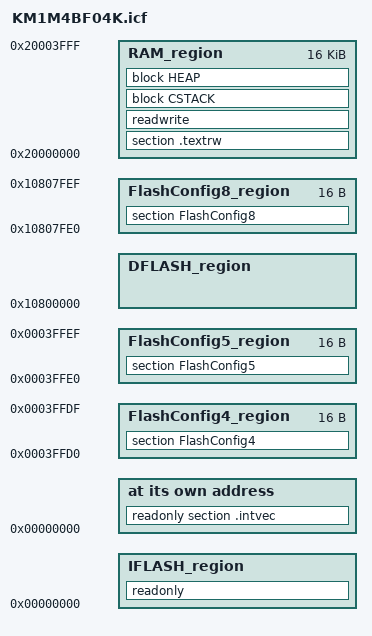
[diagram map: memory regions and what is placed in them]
/*###ICF### Section handled by ICF editor, don't touch! ****/
/*-Editor annotation file-*/
/* IcfEditorFile="$TOOLKIT_DIR$\config\ide\IcfEditor\cortex_v1_0.xml" */
/*-Specials-*/
define symbol __ICFEDIT_intvec_start__ = 0x00000000;
/*-Memory Regions-*/
define symbol __ICFEDIT_region_RAM_start__       = 0x20000000;
define symbol __ICFEDIT_region_RAM_end__         = 0x20003FFF;
define symbol __ICFEDIT_region_DFLASH_start__    = 0x10800000;
define symbol __ICFEDIT_region_DFLASH_end__      = 0x10807FFF;
define symbol __ICFEDIT_region_IFLASH_start__    = 0x00000000;
define symbol __ICFEDIT_region_IFLASH_end__      = 0x00041FFF;
/*-Sizes-*/
define symbol __ICFEDIT_size_cstack__ = 0x400;
define symbol __ICFEDIT_size_heap__   = 0x800;
/**** End of ICF editor section. ###ICF###*/

/**** Special settings for target device ****/

/*- Define symbols -*/
define symbol __FlashConfig1_start__ = 0x0003FFC0;
define symbol __FlashConfig1_end__   = 0x0003FFC0;
define symbol __FlashConfig2_start__ = 0x0003FFC2;
define symbol __FlashConfig2_end__   = 0x0003FFC2;
define symbol __FlashConfig3_start__ = 0x0003FFC8;
define symbol __FlashConfig3_end__   = 0x0003FFC8;
define symbol __FlashConfig4_start__ = 0x0003FFD0;
define symbol __FlashConfig4_end__   = 0x0003FFDF;
define symbol __FlashConfig5_start__ = 0x0003FFE0;
define symbol __FlashConfig5_end__   = 0x0003FFEF;
define symbol __FlashConfig6_start__ = 0x00040FF8;
define symbol __FlashConfig6_end__   = 0x00040FF8;
define symbol __FlashConfig7_start__ = 0x00041FF8;
define symbol __FlashConfig7_end__   = 0x00041FF8;
define symbol __FlashConfig8_start__ = 0x10807FE0;
define symbol __FlashConfig8_end__   = 0x10807FEF;

/* Define the memory space of 4G bytes named "mem" */
define memory mem with size = 4G;

/*- Define region in memory -*/
define region IFLASH_region    = mem:[from __ICFEDIT_region_IFLASH_start__ to __ICFEDIT_region_IFLASH_end__] - mem:[from __FlashConfig1_start__ to __FlashConfig1_end__] - mem:[from __FlashConfig2_start__ to __FlashConfig2_end__] - mem:[from __FlashConfig3_start__ to __FlashConfig3_end__] - mem:[from __FlashConfig4_start__ to __FlashConfig4_end__] - mem:[from __FlashConfig5_start__ to __FlashConfig5_end__] - mem:[from __FlashConfig6_start__ to __FlashConfig6_end__] - mem:[from __FlashConfig7_start__ to __FlashConfig7_end__];
define region DFLASH_region    = mem:[from __ICFEDIT_region_DFLASH_start__ to __ICFEDIT_region_DFLASH_end__] - mem:[from __FlashConfig8_start__ to __FlashConfig8_end__];
define region RAM_region       = mem:[from __ICFEDIT_region_RAM_start__ to __ICFEDIT_region_RAM_end__];

define region FlashConfig1_region = mem:[from __FlashConfig1_start__ to __FlashConfig1_end__];
define region FlashConfig2_region = mem:[from __FlashConfig2_start__ to __FlashConfig2_end__];
define region FlashConfig3_region = mem:[from __FlashConfig3_start__ to __FlashConfig3_end__];
define region FlashConfig4_region = mem:[from __FlashConfig4_start__ to __FlashConfig4_end__];
define region FlashConfig5_region = mem:[from __FlashConfig5_start__ to __FlashConfig5_end__];
define region FlashConfig6_region = mem:[from __FlashConfig6_start__ to __FlashConfig6_end__];
define region FlashConfig7_region = mem:[from __FlashConfig7_start__ to __FlashConfig7_end__];
define region FlashConfig8_region = mem:[from __FlashConfig8_start__ to __FlashConfig8_end__];

/*- Define block -*/
define block CSTACK    with alignment = 8, size = __ICFEDIT_size_cstack__   { };
define block HEAP      with alignment = 8, size = __ICFEDIT_size_heap__     { };

/*- Initialize type -*/
initialize by copy { readwrite };
do not initialize  { section .noinit };

/*- Set placement in memory or region -*/
place at address mem:__ICFEDIT_intvec_start__ { readonly section .intvec };

place in IFLASH_region    { readonly };
place in RAM_region       { section .textrw, readwrite, block CSTACK, block HEAP };

place in FlashConfig1_region { section FlashConfig1 };
place in FlashConfig2_region { section FlashConfig2 };
place in FlashConfig3_region { section FlashConfig3 };
place in FlashConfig4_region { section FlashConfig4 };
place in FlashConfig5_region { section FlashConfig5 };
place in FlashConfig6_region { section FlashConfig6 };
place in FlashConfig7_region { section FlashConfig7 };
place in FlashConfig8_region { section FlashConfig8 };
